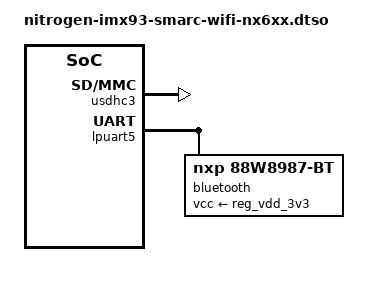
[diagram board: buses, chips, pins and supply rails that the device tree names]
// SPDX-License-Identifier: (GPL-2.0+ OR MIT)
/*
 * SDIO NX6xx module
 *
 * Copyright 2025 Ezurio LLC
 */

/dts-v1/;
/plugin/;

&reg_wifi_en {
	startup-delay-us = <20000>;
	off-on-delay-us = <100>;
};

&usdhc3 {
	status = "okay";
};

&lpuart5 {
	status = "okay";

	bluetooth {
		compatible = "nxp,88w8987-bt";
		fw-init-baudrate = <3000000>;
		vcc-supply = <&reg_vdd_3v3>;
	};
};
